# ECM3532 register map
Vendor: EtaCompute; Series: ECM35xx; File version: 1.0.0
CPU: CM3 r1p1, little endian, MPU, no FPU, 3 interrupt priority bits
Registers are 32-bit, read-write, reset 0x0 unless marked. A register's access mark holds for its fields unless they carry their own. Offsets are from the block's base; [hi:lo] are bit positions; lines under a group give offsets from that group; {n}, {i} and the like mark numbered series.

## NVIC — The Nested Vectored interrupt Controller
Base 0xE000E000
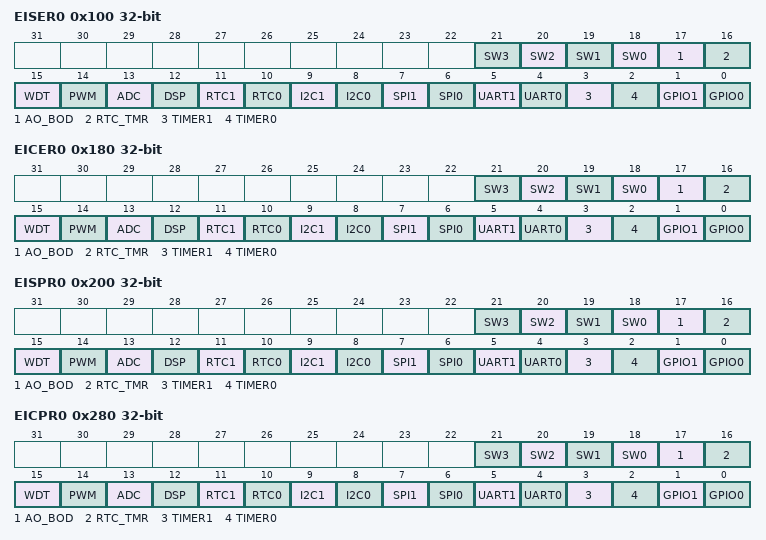
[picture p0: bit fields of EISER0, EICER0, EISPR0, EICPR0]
0x100 EISER0 — Set Interrupt Enable Bits [31:0]
  [n+18] SW{n} (n=0..3) — Enable for external Interrupt
  [17] AO_BOD — Enable for external Interrupt
  [16] RTC_TMR — Enable for external Interrupt
  [15] WDT — Enable for external Interrupt
  [14] PWM — Enable for external Interrupt
  [13] ADC — Enable for external Interrupt
  [12] DSP — Enable for external Interrupt
  [11] RTC1 — Enable for external Interrupt
  [10] RTC0 — Enable for external Interrupt
  [9] I2C1 — Enable for external Interrupt
  [8] I2C0 — Enable for external Interrupt
  [7] SPI1 — Enable for external Interrupt
  [6] SPI0 — Enable for external Interrupt
  [5] UART1 — Enable for external Interrupt
  [4] UART0 — Enable for external Interrupt
  [3] TIMER1 — Enable for external Interrupt
  [2] TIMER0 — Enable for external Interrupt
  [1] GPIO1 — Enable for external Interrupt
  [0] GPIO0 — Enable for external Interrupt
0x180 EICER0 — Clear Interrupt Enable Bits [31:0]
  [n+18] SW{n} (n=0..3) — Clear enable for external Interrupt
  [17] AO_BOD — Clear enable for external Interrupt
  [16] RTC_TMR — Clear enable for external Interrupt
  [15] WDT — Clear enable for external Interrupt
  [14] PWM — Clear enable for external Interrupt
  [13] ADC — Clear enable for external Interrupt
  [12] DSP — Clear enable for external Interrupt
  [11] RTC1 — Clear enable for external Interrupt
  [10] RTC0 — Clear enable for external Interrupt
  [9] I2C1 — Clear enable for external Interrupt
  [8] I2C0 — Clear enable for external Interrupt
  [7] SPI1 — Clear enable for external Interrupt
  [6] SPI0 — Clear enable for external Interrupt
  [5] UART1 — Clear enable for external Interrupt
  [4] UART0 — Clear enable for external Interrupt
  [3] TIMER1 — Clear enable for external Interrupt
  [2] TIMER0 — Clear enable for external Interrupt
  [1] GPIO1 — Clear enable for external Interrupt
  [0] GPIO0 — Clear enable for external Interrupt
0x200 EISPR0 — Interrupt Set Pending Register 0 Bits [31:0]
  [n+18] SW{n} (n=0..3) — Set interrupt pending bit
  [17] AO_BOD — Set interrupt pending bit
  [16] RTC_TMR — Set interrupt pending bit
  [15] WDT — Set interrupt pending bit
  [14] PWM — Set interrupt pending bit
  [13] ADC — Set interrupt pending bit
  [12] DSP — Set interrupt pending bit
  [11] RTC1 — Set interrupt pending bit
  [10] RTC0 — Set interrupt pending bit
  [9] I2C1 — Set interrupt pending bit
  [8] I2C0 — Set interrupt pending bit
  [7] SPI1 — Set interrupt pending bit
  [6] SPI0 — Set interrupt pending bit
  [5] UART1 — Set interrupt pending bit
  [4] UART0 — Set interrupt pending bit
  [3] TIMER1 — Set interrupt pending bit
  [2] TIMER0 — Set interrupt pending bit
  [1] GPIO1 — Set interrupt pending bit
  [0] GPIO0 — Set interrupt pending bit
0x280 EICPR0 — Interrupt Clear Pending Register 0 Bits [31:0]
  [n+18] SW{n} (n=0..3) — Clear interrupt pending bit
  [17] AO_BOD — Clear interrupt pending bit
  [16] RTC_TMR — Clear interrupt pending bit
  [15] WDT — Clear interrupt pending bit
  [14] PWM — Clear interrupt pending bit
  [13] ADC — Clear interrupt pending bit
  [12] DSP — Clear interrupt pending bit
  [11] RTC1 — Clear interrupt pending bit
  [10] RTC0 — Clear interrupt pending bit
  [9] I2C1 — Clear interrupt pending bit
  [8] I2C0 — Clear interrupt pending bit
  [7] SPI1 — Clear interrupt pending bit
  [6] SPI0 — Clear interrupt pending bit
  [5] UART1 — Clear interrupt pending bit
  [4] UART0 — Clear interrupt pending bit
  [3] TIMER1 — Clear interrupt pending bit
  [2] TIMER0 — Clear interrupt pending bit
  [1] GPIO1 — Clear interrupt pending bit
  [0] GPIO0 — Clear interrupt pending bit
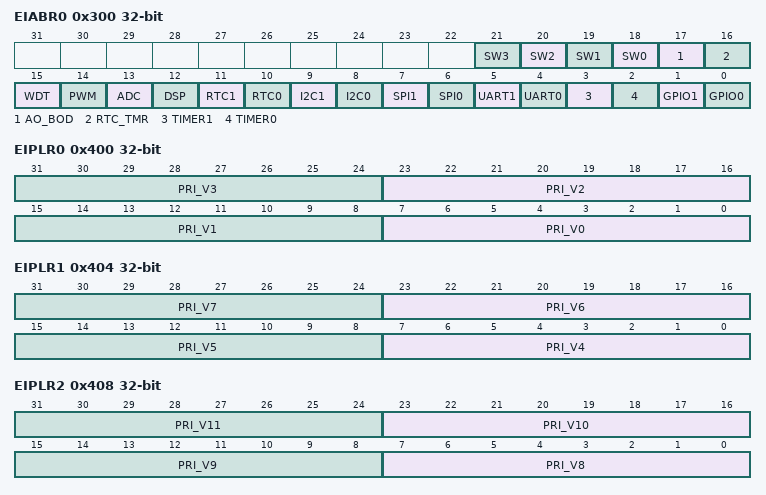
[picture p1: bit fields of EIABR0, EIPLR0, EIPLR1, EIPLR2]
0x300 EIABR0 — Interrupt Active Bits Register 0 Bits [31:0]. These bits indicate which vectors are active.
  [n+18] SW{n} (n=0..3) — Interrupt active status bit
  [17] AO_BOD — Interrupt active status bit
  [16] RTC_TMR — Interrupt active status bit
  [15] WDT — Interrupt active status bit
  [14] PWM — Interrupt active status bit
  [13] ADC — Interrupt active status bit
  [12] DSP — Interrupt active status bit
  [11] RTC1 — Interrupt active status bit
  [10] RTC0 — Interrupt active status bit
  [9] I2C1 — Interrupt active status bit
  [8] I2C0 — Interrupt active status bit
  [7] SPI1 — Interrupt active status bit
  [6] SPI0 — Interrupt active status bit
  [5] UART1 — Interrupt active status bit
  [4] UART0 — Interrupt active status bit
  [3] TIMER1 — Interrupt active status bit
  [2] TIMER0 — Interrupt active status bit
  [1] GPIO1 — Interrupt active status bit
  [0] GPIO0 — Interrupt active status bit
0x400 EIPLR0 — Interrupt Priority Setting Register for vectors [3:0]
  [8n+7:8n] PRI_V{n} (n=0..3) — Bit [7:5] sets the priority level from 0 to 7.
0x404 EIPLR1 — Interrupt Priority Setting Register for vectors [7:4]
  [8n-25:8n-32] PRI_V{n} (n=4..7) — Bit [7:5] sets the priority level from 0 to 7.
0x408 EIPLR2 — Interrupt Priority Setting Register for vectors [11:8]
  [8n-57:8n-64] PRI_V{n} (n=8..11) — Bit [7:5] sets the priority level from 0 to 7.
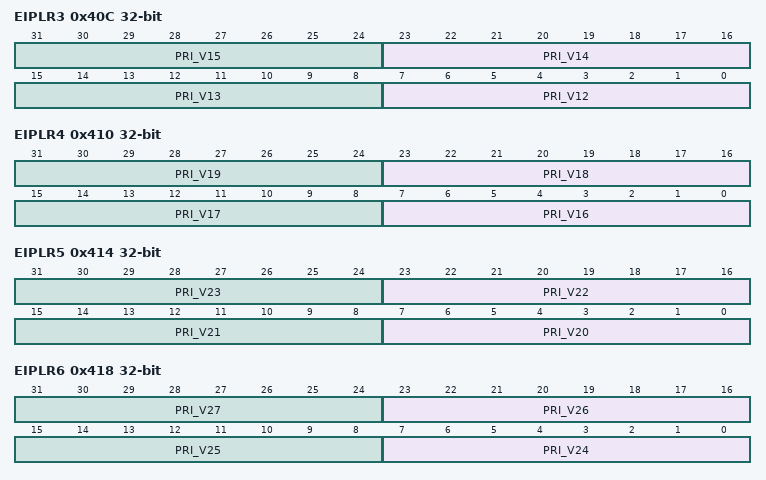
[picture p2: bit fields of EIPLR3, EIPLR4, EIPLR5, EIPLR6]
0x40C EIPLR3 — Interrupt Priority Setting Register for vectors [15:12]
  [8n-89:8n-96] PRI_V{n} (n=12..15) — Bit [7:5] sets the priority level from 0 to 7.
0x410 EIPLR4 — Interrupt Priority Setting Register for vectors [19:16]
  [8n-121:8n-128] PRI_V{n} (n=16..19) — Bit [7:5] sets the priority level from 0 to 7.
0x414 EIPLR5 — Interrupt Priority Setting Register for vectors [23:20]
  [8n-153:8n-160] PRI_V{n} (n=20..23) — Bit [7:5] sets the priority level from 0 to 7.
0x418 EIPLR6 — Interrupt Priority Setting Register for vectors [27:24]
  [8n-185:8n-192] PRI_V{n} (n=24..27) — Bit [7:5] sets the priority level from 0 to 7.
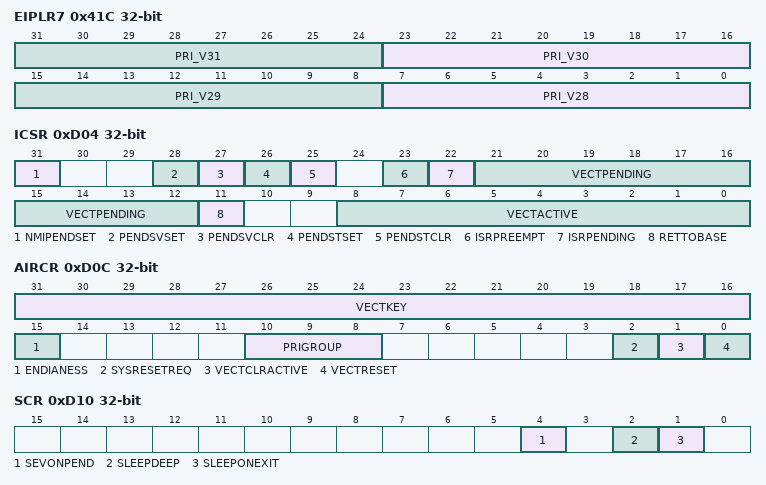
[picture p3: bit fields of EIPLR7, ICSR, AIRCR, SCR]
0x41C EIPLR7 — Interrupt Priority Setting Register for vectors [31:28]
  [8n-217:8n-224] PRI_V{n} (n=28..31) — Bit [7:5] sets the priority level from 0 to 7.
0xD04 ICSR — Interrupt Control and State
  [31] NMIPENDSET — NMI Pended
  [28] PENDSVSET — Write 1 to pend system call; Read value indicates pending status
  [27] PENDSVCLR wo — Write 1 to clear PendSV pending status
  [26] PENDSTSET — Write 1 to pend systick exception; Read value indicates pending status
  [25] PENDSTCLR wo — Write 1 to clear Systick pending status
  [23] ISRPREEMPT ro — Indicate that a pending interrupt is going to be active in next step (for debug)
  [22] ISRPENDING ro — external interrupt pending (excluding system exceptions like NMI for fault)
  [21:12] VECTPENDING ro — Pending ISR number
  [11] RETTOBASE ro — Set to 1 when the processor is running an exception handler and will return to thread level if interrupt return and no other exceptions pending
  [8:0] VECTACTIVE ro — Current running interrupt service routine
0xD0C AIRCR — Application Interrupt and Reset Control
  [31:16] VECTKEY — Access key; 0x05FA must be written to this field to write to this register; the read back value is 0xFA05.
  [15] ENDIANESS ro — endianness for data; 1 for big, 0 for little.
  [10:8] PRIGROUP — Priority group
  [2] SYSRESETREQ wo — Request chip control logic to generate a reset
  [1] VECTCLRACTIVE wo — Clear all active state information for exceptions; typically used in debug or OS to allow system to recover from system error (Reset is safer)
  [0] VECTRESET wo — Reset CortexM3 (except debug logic); will not reset circuits outside the processor
0xD10 SCR — System Control
  [4] SEVONPEND — Send Event on Pending.
  [2] SLEEPDEEP — Enable SLEEPDEEP output signal when entering sleep mode.
  [1] SLEEPONEXIT — Enable SLEEPDEEP on exit feature
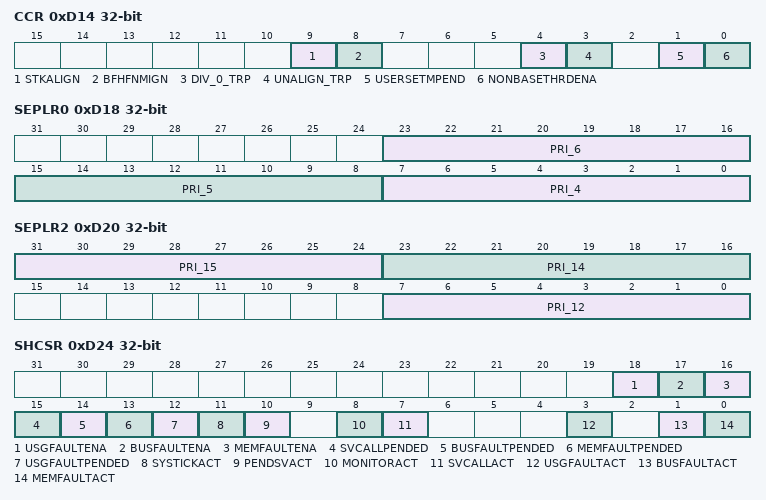
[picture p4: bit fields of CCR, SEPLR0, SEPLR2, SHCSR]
0xD14 CCR — Configuration Control
  [9] STKALIGN — Force exception stacking start in double word aligned address.
  [8] BFHFNMIGN — Ignore data bus fault during hard fault and NMI handlers
  [4] DIV_0_TRP — Trap on divide by 0
  [3] UNALIGN_TRP — Trap on unaligned access
  [1] USERSETMPEND — If set to 1, allow user code to write to Software Trigger Interrupt register
  [0] NONBASETHRDENA — Nonbase Thread Enable. If set to 1, allows exception handler to return to thread state at any level by controlling return value.
0xD18 SEPLR0 — System Exceptions Priority Setting Register for mm/bus/usage fault
  [23:16] PRI_6 — Bit [7:5] sets the priority level from 0 to 7.
  [15:8] PRI_5 — Bit [7:5] sets the priority level from 0 to 7.
  [7:0] PRI_4 — Bit [7:5] sets the priority level from 0 to 7.
0xD1C SEPLR1 — System Exceptions Priority Setting Register for SVC
  [31:24] PRI_11 — Bit [7:5] sets the priority level from 0 to 7.
0xD20 SEPLR2 — System Exceptions Priority Setting Register for debug monitor/PendSV/SYSTICK
  [31:24] PRI_15 — Bit [7:5] sets the priority level from 0 to 7.
  [23:16] PRI_14 — Bit [7:5] sets the priority level from 0 to 7.
  [7:0] PRI_12 — Bit [7:5] sets the priority level from 0 to 7.
0xD24 SHCSR — System Handler Control and State
  [18] USGFAULTENA — Usage fault handler enable
  [17] BUSFAULTENA — Bus fault handler enable
  [16] MEMFAULTENA — Memory Management fault handler enable
  [15] SVCALLPENDED — SVC pended; SVC is started but was replaced by a higher priority exception
  [14] BUSFAULTPENDED — bus fault pended; bus fault is started but was replaced by a higher priority exception
  [13] MEMFAULTPENDED — mm fault pended; mm fault is started but was replaced by a higher priority exception
  [12] USGFAULTPENDED — usage fault pended; usage fault is started but was replaced by a higher priority exception
  [11] SYSTICKACT — Read as 1 if SYSTICK exception is active
  [10] PENDSVACT — Read as 1 if PendSV exception is active
  [8] MONITORACT — Read as 1 if debug monitor exception is active
  [7] SVCALLACT — Read as 1 if SVC exception is active
  [3] USGFAULTACT — Read as 1 if USGFAULTACT exception is active
  [1] BUSFAULTACT — Read as 1 if BUSFAULTACT exception is active
  [0] MEMFAULTACT — Read as 1 if MEMFAULTACT exception is active
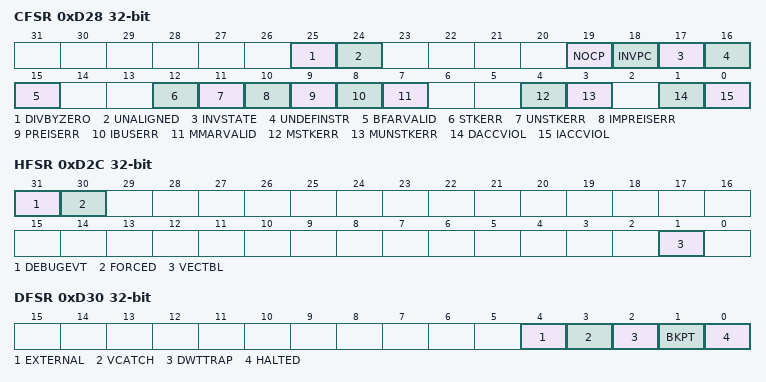
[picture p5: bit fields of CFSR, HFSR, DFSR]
0xD28 CFSR — Read the fault status, write to clear the fault
  [25] DIVBYZERO — Indicate divide by zero takes place (can only set if DIV_0_TRP is set)
  [24] UNALIGNED — Indicate unaligned access takes place (can only set if UNALIGN_TRP is set)
  [19] NOCP — Attemps to execute a coprocessor instruction
  [18] INVPC — Attemps to do exception with bad value in EXC_RETURN number
  [17] INVSTATE — Attemps to switch to invalid state
  [16] UNDEFINSTR — Attemps to execute an undefined instruction
  [15] BFARVALID ro — Indicates BFAR is valid
  [12] STKERR — Stacking error
  [11] UNSTKERR — Unstacking error
  [10] IMPREISERR — Imprecise data access violation
  [9] PREISERR — Precise data access violation
  [8] IBUSERR — Instruction access violation
  [7] MMARVALID ro — Indicates MMAR is valid
  [4] MSTKERR — Stacking error
  [3] MUNSTKERR — Unstacking error
  [1] DACCVIOL — data access violation
  [0] IACCVIOL — Instruction access violation
0xD2C HFSR — Read the fault status, write to clear the fault
  [31] DEBUGEVT — Indicate hard fault is triggered by debug event
  [30] FORCED — Indicate hard fault is taken because of mm/bus/usage fault
  [1] VECTBL — Indicate hard fault is caused by failed vetor fetch
0xD30 DFSR — Read the fault status, write to clear the fault
  [4] EXTERNAL — EDBGRQ signal asserted
  [3] VCATCH — Vector fetch occurred
  [2] DWTTRAP — DWT match occurred
  [1] BKPT — BKPT instruction executed
  [0] HALTED — HALTED requested in NVIC
0xD34 MMAR — memory manage address that caused the fault
  [31:0] MMAR ro — Address that cuased memory manage fault
0xD38 BFAR — address that caused bus fault
  [31:0] BFAR ro — Address that cuased bus fault
0xF00 STIR — Writing the interrupt number sets the pending bit of the interrupt.
  [8:0] INTID wo — value written is the interrupt number issued
